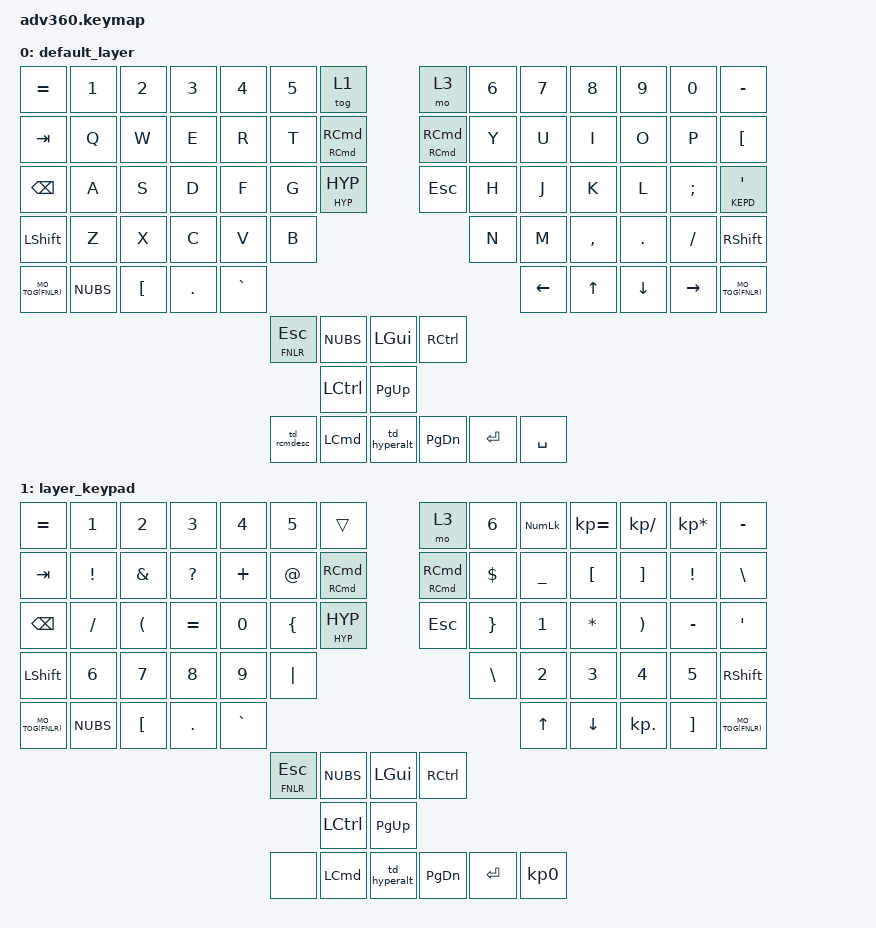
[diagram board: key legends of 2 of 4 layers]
#include <behaviors.dtsi>
#include <dt-bindings/zmk/keys.h>
#include <dt-bindings/zmk/bt.h>
#include <dt-bindings/zmk/rgb.h>
#include <dt-bindings/zmk/backlight.h>

#define HYPER(key) LS(LC(LA(LG(key))))
#define HYP    LS(LC(LA(LGUI)))

#define MACLOCK  LG(LC(Q))

#define BROWSER_SEARCH LG(F)
#define BROWSER_NEWTAB LG(T)
#define BROWSER_CLOSETAB LG(W)
#define BROWSER_NEXTTAB LG(LA(RIGHT))
#define BROWSER_PREVTAB LG(LA(LEFT))

#define BASE   0
#define KEPD   1
#define FNLR   2

#define MO_TOG(layer) &mtg layer layer
#define HYPSPC &htsk SPACE HYP


#define NAV_LEFT  &mt HOME     LEFT    // tap: left  | long-tap: beginning of line
#define NAV_RIGHT &mt END      RIGHT   // tap: right | long-tap: end       of line
#define NAV_UP    &mt LC(HOME) UP      // tap: up    | long-tap: beginning of document
#define NAV_DOWN  &mt LC(END)  DOWN    // tap: down  | long-tap: end       of document
#define NAV_BSPC  &mt LC(BSPC) BSPC    // tap: bspc  | long-tap: delete word backward
#define NAV_DEL   &mt LC(DEL)  DEL     // tap: del   | long-tap: delete word forward


&mt {
    flavor = "tap-preferred";
    tapping-term-ms = <220>;
    quick-tap-ms = <220>;              // repeat on tap-into-hold
    hold-trigger-key-positions = <0>;  // tap on interrupt
};



#define CANCEL      &kp K_CANCEL       // cancel caps-word and num-word
#define DSK_PREV    &kp LG(LC(LEFT))   // previous desktop
#define DSK_NEXT    &kp LG(LC(RIGHT))  // next     desktop


#define QUICK_TAP_MS 175
#define COMBO_TIMEOUT 30

#define ___ &kp
#define OOO &trans
#define XXX &none

&sk {  // sticky-key config
    release-after-ms = <2000>;
    quick-release;             // no double capitalization when rolling keys
};

&sl {  // sticky-layer config
    ignore-modifiers;
    release-after-ms = <2000>;
};

&lt {  // layer-tap config
    flavor = "balanced";
    tapping-term-ms = <200>;
    quick-tap-ms = <QUICK_TAP_MS>;
};


/ {
  behaviors {
    #include "macros.dtsi"
      #include "version.dtsi"
      #ifndef VERSION_MACRO
      macro_ver: macro_ver {
        compatible = "zmk,behavior-macro";
        label = "macro_version";
        #binding-cells = <0>;
        bindings = <&kp RET>;
      };
      #endif

    mtg: behavior_mo_tog {
                compatible = "zmk,behavior-hold-tap";
                label = "mtg";
                #binding-cells = <2>;
                flavor = "hold-preferred";
                tapping-term-ms = <200>;
                bindings = <&mo>, <&sl>;
            };
    htsk: behavior_htsk {
                compatible = "zmk,behavior-hold-tap";
                label = "htsk";
                #binding-cells = <2>;
                flavor = "hold-preferred";
                tapping-term-ms = <150>;
                quick-tap-ms = <200>;
                bindings = <&kp>, <&skq>;
            };
     skq: sticky_key_quick_release {
        compatible = "zmk,behavior-sticky-key";
        label = "STICKY_KEY_QUICK_RELEASE";
        #binding-cells = <1>;
        bindings = <&kp>;
        release-after-ms = <3500>;
        quick-release;
        ignore-modifiers;
      };

   td_rcmdesc: tap_dance_rcmd_esc {
              compatible = "zmk,behavior-tap-dance";
              label = "TAP_DANCE_RCMD_ESC";
              #binding-cells = <0>;
              tapping-term-ms = <350>;
              bindings = <&sl KEPD>, <&kp ESC>;
    };

   td_hyperalt: tap_dance_hyper_alt {
              compatible = "zmk,behavior-tap-dance";
              label = "TAP_DANCE_HYPERALT";
              #binding-cells = <0>;
              tapping-term-ms = <350>;
              bindings = <&kp LALT>, <&htsk HYP HYP>;
    };
};


combos {
      compatible = "zmk,combos";
      combo_esc {
          timeout-ms = <COMBO_TIMEOUT>;
          key-positions = <30 31>;
          bindings = <&kp ESC>;
      };
       combo_esc2 {
                timeout-ms = <COMBO_TIMEOUT>;
                key-positions = <37 38>;
                bindings = <&kp ESC>;
            };
  };

keymap {
    compatible = "zmk,keymap";
    default_layer {
      bindings = <
        &kp EQUAL       &kp N1        &kp N2        &kp N3        &kp N4           &kp N5            &tog 1                             &mo 3            &kp N6          &kp N7         &kp N8         &kp N9            &kp N0            &kp MINUS
        &kp TAB         &kp Q         &kp W         &kp E         &kp R            &kp T             &htsk RCMD RCMD                    &htsk RCMD RCMD  &kp Y           &kp U          &kp I          &kp O             &kp P             &kp LBKT
        &kp BACKSPACE   &kp A         &kp S         &kp D         &kp F            &kp G             &htsk HYP HYP                      &kp ESC          &kp H           &kp J          &kp K          &kp L             &kp SEMI          &lt KEPD SQT
        &kp LSHFT       &kp Z         &kp X         &kp C         &kp V            &kp B                                                                 &kp N           &kp M          &kp COMMA      &kp DOT           &kp FSLH          &kp RSHFT
        MO_TOG(FNLR)    &kp NUBS      &kp LBKT      &kp DOT       &kp GRAVE                                                                                              &kp LEFT       &kp UP         &kp DOWN          &kp RIGHT         MO_TOG(FNLR)

                                                                                            &lt FNLR ESC    &kp NUBS        &kp LGUI     &kp RCTRL
                                                                                                            &kp LCTRL       &kp PG_UP
                                                                               &td_rcmdesc   &kp LCMD       &td_hyperalt    &kp PG_DN    &kp ENTER  &kp SPACE
     >;};

    layer_keypad {
      bindings = <
        &kp EQUAL       &kp N1        &kp N2        &kp N3        &kp N4           &kp N5            &trans                             &mo 3            &kp N6          &kp KP_NUM     &kp KP_EQUAL   &kp KP_DIVIDE     &kp KP_MULTIPLY   &kp MINUS
        &kp TAB         &kp EXCL      &kp AMPS      &kp QMARK     &kp PLUS         &kp AT            &htsk RCMD RCMD                    &htsk RCMD RCMD  &kp DOLLAR      &kp UNDER      &kp LBKT       &kp RBKT          &kp EXCL          &kp BSLH
        &kp BACKSPACE   &kp SLASH     &kp LPAR      &kp EQUAL     &kp N0           &kp LBRC          &htsk HYP HYP                      &kp ESC          &kp RBRC        &kp N1         &kp STAR       &kp RPAR          &kp MINUS         &kp SQT
        &kp LSHFT       &kp N6        &kp N7        &kp N8        &kp N9           &kp PIPE                                                              &kp BSLH        &kp N2         &kp N3         &kp N4            &kp N5            &kp RSHFT
        MO_TOG(FNLR)    &kp NUBS      &kp LBKT      &kp DOT       &kp GRAVE                                                                                              &kp UP         &kp DOWN       &kp KP_DOT        &kp RBKT          MO_TOG(FNLR)

                                                                                                  &lt FNLR ESC    &kp NUBS        &kp LGUI     &kp RCTRL
                                                                                                                  &kp LCTRL       &kp PG_UP
                                                                                         &none     &kp LCMD       &td_hyperalt    &kp PG_DN    &kp ENTER   &kp KP_N0
    >;};

    layer_fn {
      bindings = <
        &kp ESCAPE      &kp F1        &kp F2        &kp F3        &kp F4           &kp F5            &kp F6                             &mo 3            &kp F7                  &kp F8              &kp F9               &kp F10              &kp F11           &kp F12
        &trans          ___ F11       ___ F12       OOO           OOO              OOO               &none                              &none            &kp BROWSER_CLOSETAB    &kp BROWSER_PREVTAB &kp BROWSER_NEXTTAB  &kp BROWSER_NEXTTAB  &kp ASTERISK      &trans
        &trans          ___ F1        ___ F2        ___ F3        ___ F4           ___ F5            &none                              &none            &trans                  &sk RSHFT           &sk RCTRL            &sk RALT             &sk LGUI          &trans
        &trans          ___ F6        ___ F7        ___ F8        ___ F9           ___ F10                                                               &trans                  &trans              &trans               &trans               &trans            &trans
        &trans          &kp NUBS      &kp LBKT      &kp DOT       &kp GRAVE                                                                                                      &trans              &trans               &trans               &trans            &trans


                                                                                                       &none   &none       &trans    &trans
                                                                                                               &trans      &trans
                                                                                           &none       &trans  &trans      &trans    &trans     &trans





      >;};

    layer_mod {
     bindings = <
        &none           &bt BT_SEL 0  &bt BT_SEL 1  &bt BT_SEL 2  &bt BT_SEL 3     &bt BT_SEL 4           &tog BASE                     &tog BASE                  &bt BT_SEL 0            &bt BT_SEL 1        &bt BT_SEL 2         &bt BT_SEL 3         &bt BT_SEL 4      &none
        &none           &none         &none         &none         &none            &none                  &bootloader                   &bootloader                &none                   &none               &none                &none                &none             &none
        &none           &none         &none         &none         &none            &none                  &rgb_ug RGB_MEFS_CMD 5        &rgb_ug RGB_MEFS_CMD 5     &none                   &none               &none                &none                &none             &none
        &none           &none         &none         &none         &macro_ver            &none                                                                           &none                   &none               &none                &none                &none             &none
        &none           &none         &none         &bl BL_INC    &bl BL_DEC       &rgb_ug RGB_TOG                                                                                         &bl BL_DEC          &none                &none                &none             &none


                                                                                                   &bt BT_CLR    &none    &bt BT_CLR  &bt BT_CLR
                                                                                                                 &none    &none
                                                                                             &bl BL_TOG  &none   &none    &bl BL_TOG  &rgb_ug RGB_TOG   &bl BL_INC





      >;};
  };
};
